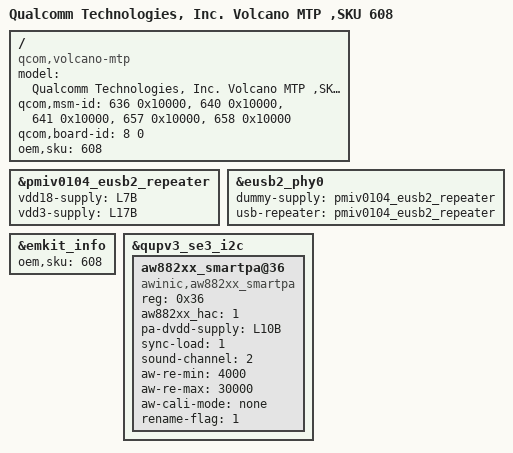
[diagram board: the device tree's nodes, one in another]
/dts-v1/;
/plugin/;

/* this file is copy from volcano-mtp-overlay.dts */

#include "volcano-mtp.dtsi"
#include "volcano-pmiv0104.dtsi"

/ {
	model = "Qualcomm Technologies, Inc. Volcano MTP ,SKU 608 ";
	compatible = "qcom,volcano-mtp", "qcom,volcano", "qcom,volcanop-mtp", "qcom,volcanop", "qcom,mtp";
	qcom,msm-id = <636 0x10000>, <640 0x10000>, <641 0x10000>, <657 0x10000>, <658 0x10000>;
	qcom,board-id = <8 0>;
	oem,sku = <608>;
};

&pmiv0104_eusb2_repeater {
	status = "ok";
	vdd18-supply = <&L7B>;
	vdd3-supply = <&L17B>;
};

&eusb2_phy0 {
	dummy-supply = <&pmiv0104_eusb2_repeater>;
	usb-repeater = <&pmiv0104_eusb2_repeater>;
};

/* SKU Information */
&emkit_info {
	oem,sku = <608>;
};

/* fps audio 3 PA dtsi, if sku have 3 PA, please add this, like sku 605. if only have 2 PA, delete this. */
/*aw882xx I2c is used GPIO_15 & GPIO_16 should define as I2C in QUPAC_Access.c * QUP_0 SE3  qup0_se3_l0 qup0_se3_l1*/
&qupv3_se3_i2c {
    status = "ok";

    aw882xx_smartpa@36 {
    compatible = "awinic,aw882xx_smartpa";
    reg = <0x36>;
    aw882xx_hac = <1>;
    pa-dvdd-supply = <&L10B>;
    sync-load = <1>;
    sound-channel = <2>;
    aw-re-min = <4000>;
    aw-re-max= <30000>;
    aw-cali-mode = "none";
    rename-flag = <1>;
    status = "okay";
    };
};
